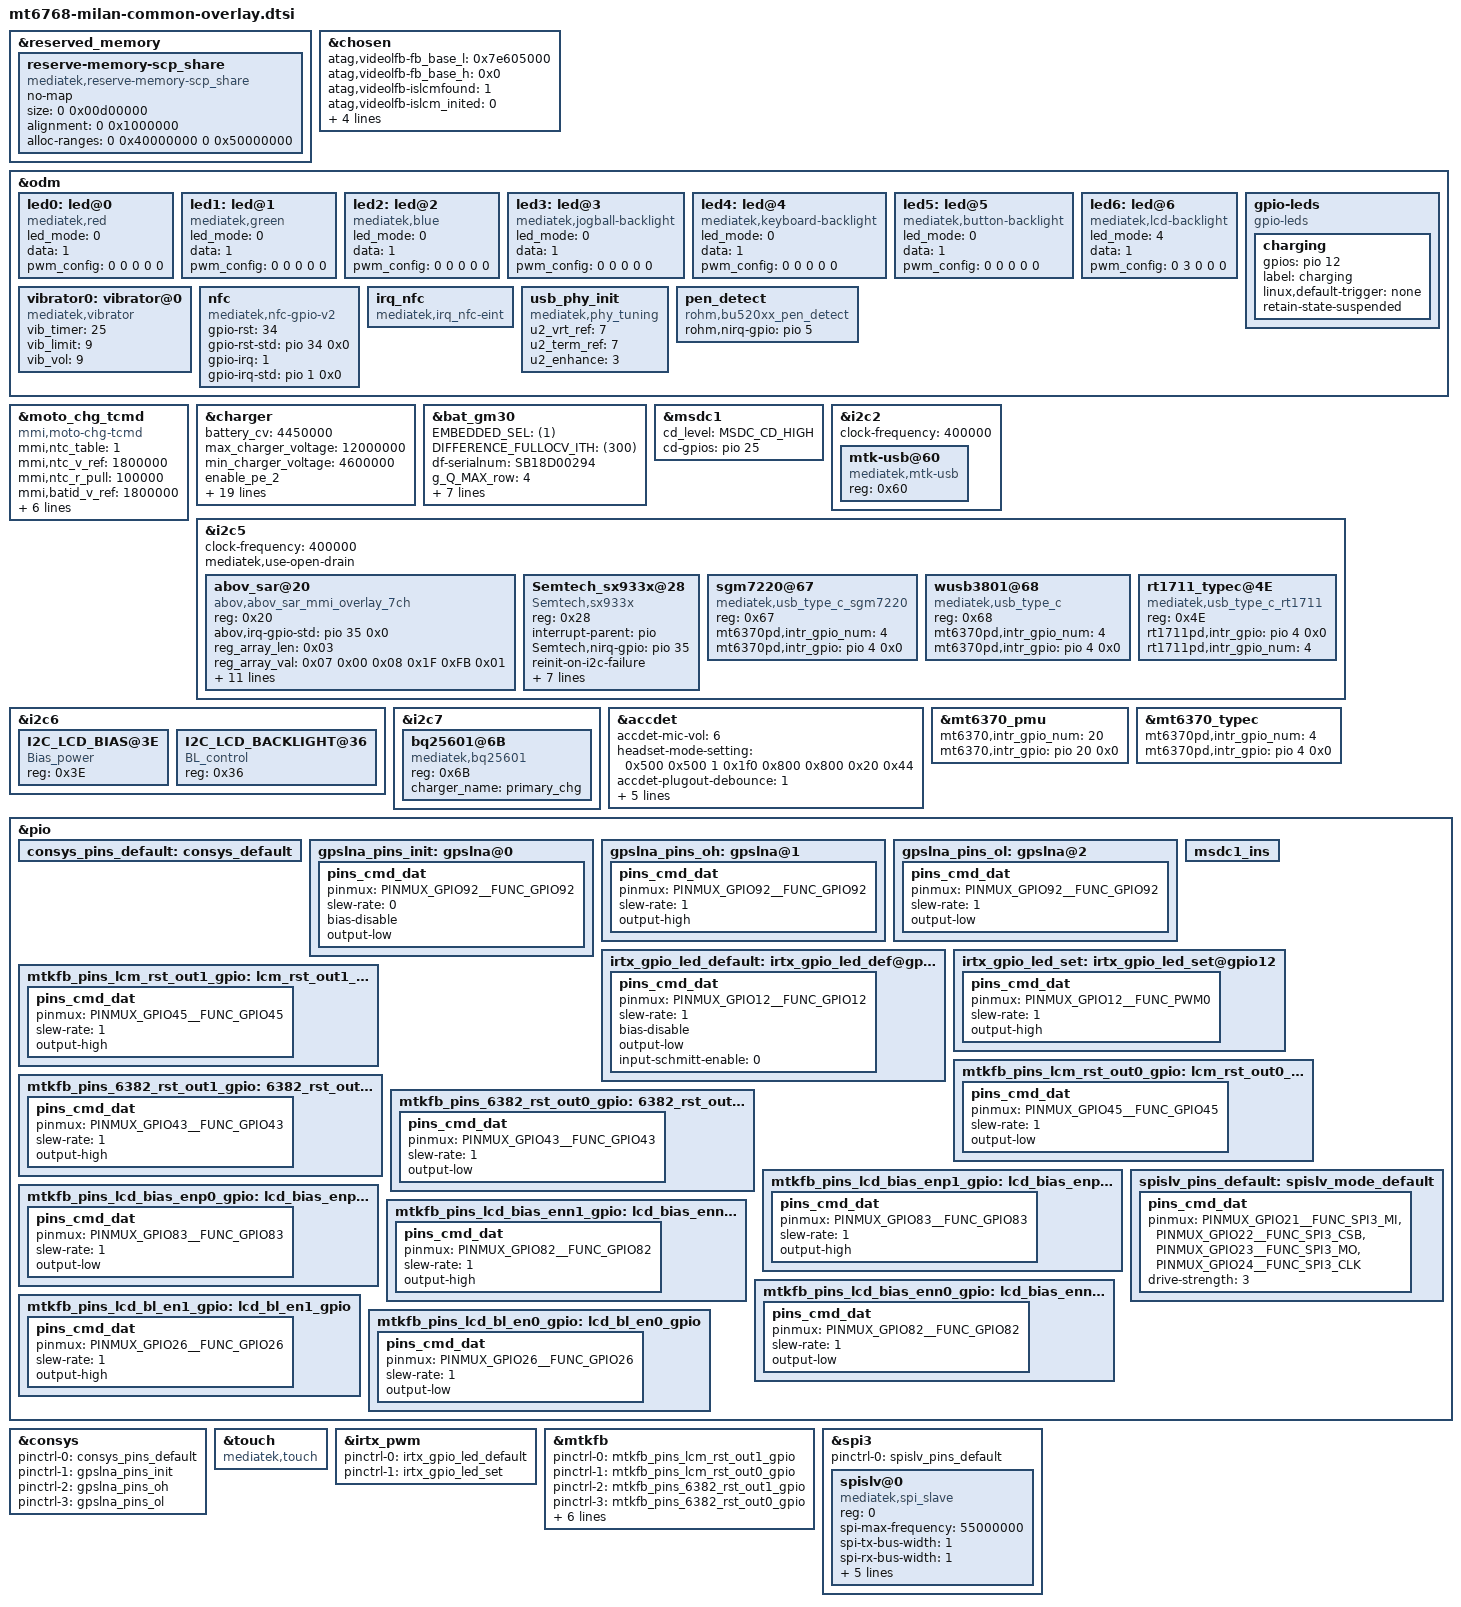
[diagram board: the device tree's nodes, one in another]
/* Copyright (c) 2021, Motorola Mobility Inc. All rights reserved.
 *
 * This program is free software; you can redistribute it and/or modify
 * it under the terms of the GNU General Public License version 2 and
 * only version 2 as published by the Free Software Foundation.
 *
 * This program is distributed in the hope that it will be useful,
 * but WITHOUT ANY WARRANTY; without even the implied warranty of
 * MERCHANTABILITY or FITNESS FOR A PARTICULAR PURPOSE.  See the
 * GNU General Public License for more details.
 */

#include "mediatek/mt6768-moto-common-overlay.dtsi"
#include "mediatek/mt6768-milan-audio-overlay.dtsi"
#include "mediatek/cust_mt6768_milan_touch_1080x2460.dtsi"
#include "dt-bindings/mmc/mt6768-msdc.h"

&reserved_memory {
	reserve-memory-scp_share {
		compatible = "mediatek,reserve-memory-scp_share";
		no-map;
		size = <0 0x00d00000>;
		alignment = <0 0x1000000>;
		alloc-ranges = <0 0x40000000 0 0x50000000>;
	};
};

/* chosen */
&chosen {

	atag,videolfb-fb_base_l = <0x7e605000>;
	atag,videolfb-fb_base_h = <0x0>;
	atag,videolfb-islcmfound = <1>;
	atag,videolfb-islcm_inited = <0>;
	atag,videolfb-fps= <6000>;
	atag,videolfb-vramSize= <0x017e8000>;
	atag,videolfb-lcmname=
		"hx83112b_fhdp_dsi_cmd_auo_rt5081_drv";
};

&odm {
	led0:led@0 {
		compatible = "mediatek,red";
		led_mode = <0>;
		data = <1>;
		pwm_config = <0 0 0 0 0>;
	};
	led1:led@1 {
		compatible = "mediatek,green";
		led_mode = <0>;
		data = <1>;
		pwm_config = <0 0 0 0 0>;
	};
	led2:led@2 {
		compatible = "mediatek,blue";
		led_mode = <0>;
		data = <1>;
		pwm_config = <0 0 0 0 0>;
	};
	led3:led@3 {
		compatible = "mediatek,jogball-backlight";
		led_mode = <0>;
		data = <1>;
		pwm_config = <0 0 0 0 0>;
	};
	led4:led@4 {
		compatible = "mediatek,keyboard-backlight";
		led_mode = <0>;
		data = <1>;
		pwm_config = <0 0 0 0 0>;
	};
	led5:led@5 {
		compatible = "mediatek,button-backlight";
		led_mode = <0>;
		data = <1>;
		pwm_config = <0 0 0 0 0>;
	};
	led6:led@6 {
		compatible = "mediatek,lcd-backlight";
		led_mode = <4>;
		data = <1>;
		pwm_config = <0 3 0 0 0>;
	};
	gpio-leds {
		compatible = "gpio-leds";
		status = "okay";
		charging {
		        gpios = <&pio 12 0x0>;
		        label = "charging";
		        linux,default-trigger = "none";
		        retain-state-suspended;
		};
	};
	vibrator0:vibrator@0 {
		compatible = "mediatek,vibrator";
		vib_timer = <25>;
		vib_limit = <9>;
		vib_vol= <9>;
	};
        nfc:nfc {
		compatible = "mediatek,nfc-gpio-v2";
		gpio-rst = <34>;
		gpio-rst-std = <&pio 34 0x0>;
		gpio-irq = <1>;
		gpio-irq-std = <&pio 1 0x0>;
	};

	irq_nfc: irq_nfc {
		compatible = "mediatek,irq_nfc-eint";
	};
    usb_phy_init:usb_phy_init {
        compatible = "mediatek,phy_tuning";
        u2_vrt_ref = <7>;
        u2_term_ref = <7>;
        u2_enhance = <3>;
    };
};

&moto_chg_tcmd {
                compatible = "mmi,moto-chg-tcmd";
                status = "okay";

                mmi,ntc_table = <1>;
                mmi,ntc_v_ref = <1800000>;
                mmi,ntc_r_pull = <100000>;

                mmi,batid_v_ref = <1800000>;
                mmi,batid_r_pull = <100000>;

                mmi,adc-channel-cpu = <0>;
                mmi,adc-channel-charger = <2>;
                mmi,adc-channel-pa = <1>;
                mmi,adc-channel-batid = <3>;
                mmi,adc-channel-vbat = <100>;
};

&charger {
        /* common */
        battery_cv = <4450000>;
        max_charger_voltage = <12000000>;
        min_charger_voltage = <4600000>;

        enable_pe_2;
        enable_sw_jeita;

        /* charging current */
        usb_charger_current_suspend = <0>;
        usb_charger_current_unconfigured = <70000>;
        usb_charger_current_configured = <500000>;
        usb_charger_current = <500000>;
        ac_charger_current = <2000000>;
        ac_charger_input_current = <2000000>;
        non_std_ac_charger_current = <1000000>;
        charging_host_charger_current = <1500000>;
        apple_1_0a_charger_current = <650000>;
        apple_2_1a_charger_current = <800000>;
        ta_ac_charger_current = <2000000>;

        /*mmi config*/
        mmi,iterm-ma = <242>;
        mmi,mmi-temp-zones = <0 4200 970 0>,
                        <10 4200 2500 970>,
                        <15 0 2500 2500>,
                        <45 0 3000 3000>,
                        <60 4200 2500 0>;
        mmi,enable-charging-limit;
        mmi,upper-limit-capacity = <65>;
        mmi,lower-limit-capacity = <60>;
};

&bat_gm30 {
        EMBEDDED_SEL = <(1)>;   /* embedded battery.*/
        DIFFERENCE_FULLOCV_ITH = <(300)>;       /*Charging termination current.*/
	  df-serialnum = "SB18D00294";
	  g_Q_MAX_row = <4>;
	  g_Q_MAX_col = <10>;
	  g_Q_MAX = <
		/*bat1,   bat2,   bat3,    bat4*/
		5010 5010 5010 5010/*T0*/
		5001 5001 5001 5001/*T1*/
		5098 5098 5098 5098/*T2*/
		5098 5098 5098 5098/*T3*/
		4851 4851 4851 4851/*T4*/
		3488 3488 3488 3488/*T5*/
		3488 3488 3488 3488/*T6*/
		3488 3488 3488 3488/*T7*/
		3488 3488 3488 3488/*T8*/
		3488 3488 3488 3488/*T9*/
	  >;
	  g_Q_MAX_H_CURRENT_row = <4>;
	  g_Q_MAX_H_CURRENT_col = <10>;
	  g_Q_MAX_H_CURRENT = <
		/*bat1,   bat2,   bat3,    bat4*/
		5010 5010 5010 5010/*T0*/
		5001 5001 5001 5001/*T1*/
		5098 5098 5098 5098/*T2*/
		5098 5098 5098 5098/*T3*/
		4851 4851 4851 4851/*T4*/
		3488 3488 3488 3488/*T5*/
		3488 3488 3488 3488/*T6*/
		3488 3488 3488 3488/*T7*/
		3488 3488 3488 3488/*T8*/
		3488 3488 3488 3488/*T9*/
	  >;
        #include "bat_setting/mt6768_battery_table_MD50_atl_5000mah_ext.dtsi"
};

&msdc1 {
        cd_level = /bits/ 8 <MSDC_CD_HIGH>;
	cd-gpios = <&pio 25 0>;
};

&i2c2 {
	clock-frequency = <400000>;

	mtk-usb@60 {
		compatible = "mediatek,mtk-usb";
		reg = <0x60>;
		status = "okay";
	};
};

&i2c5 {
    clock-frequency = <400000>;
    abov_sar@20 {
        compatible = "abov,abov_sar_mmi_overlay_7ch";
        reg = <0x20>;
        abov,irq-gpio-std = <&pio 35 0x0>;        //interrup gpio number,based on actual circuit configuration
        reg_array_len = <0x03>;
        reg_array_val = <0x07 0x00 0x08 0x1F 0xFB 0x01>;
        cap,use_channel_ch0 = <0x00>;
        cap,use_channel_ch1 = <0x01>;
        cap,use_channel_ch2 = <0x02>;
        ch0_name = "capsense_bottom_right";
        ch1_name = "capsense_bottom_left";
        ch2_name = "capsense_top";
        label = "AbovCapSense";  //firmware name,need pused AbovCapSense.BIN into /vendor/firmware/
        cap,channel_number = <0x03>;
        cap,fw_mode_ret = <0x39>;
        button_mask = <0x15>;
        cap,flash_erase_time = <1400>;
        status = "okay";
    };

    Semtech_sx933x@28 {
        status = "ok";
        compatible = "Semtech,sx933x";
        reg = <0x28>;
        interrupt-parent = <&pio>;
        Semtech,nirq-gpio = <&pio 35 0x0>;
        /*use PH3/4 as the reference sensor
        set it to 0xff if the ref-phases-x is not used*/
        reinit-on-i2c-failure;
        reinit-on-irq-failure;
        Semtech,button-flag = <0x0f>;
        Semtech,ref-phases-a = <3>;
        Semtech,ref-phases-b = <4>;
        Semtech,reg-num = <83>;
        Semtech,reg-init = <
	0x8020 0x001F0000
	0x4004 0x00000074
	0x4008 0x00000000
	0x4054 0x00000400
	0x42C0 0x08000000
	0x42C4 0x0000003F
	0x800C 0x00000000
	0x8010 0x00000000
	0x8014 0x00000000
	0x8018 0x00000000
	0x801C 0x00000031
	0x8024 0x10000A6E
	0x8028 0x2FFF82C8
	0x802C 0x00000A66
	0x8030 0x3FF78024
	0x8034 0x10000A6E
	0x8038 0x3FFE82E6
	0x803C 0x10000A5E
	0x8040 0x3DFF8263
	0x8044 0x00000A66
	0x8048 0x3FBF82C0
	0x804C 0x0000088E
	0x8050 0x80001EE6
	0x8054 0x10223705
	0x8058 0x20630031
	0x805C 0x78A45000
	0x8060 0x00000000
	0x8064 0x00000000
	0x8068 0x00000000
	0x806C 0x00000000
	0x8070 0x00000000
	0x8074 0x10222605
	0x8078 0x20630031
	0x807C 0x789C5000
	0x8080 0x00000000
	0x8084 0x00440000
	0x8088 0x00000000
	0x808C 0x20002000
	0x8090 0x00010000
	0x8094 0x10223705
	0x8098 0x20630031
	0x809C 0x789C5000
	0x80A0 0x00000000
	0x80A4 0x00700000
	0x80A8 0x00000000
	0x80AC 0x1F001F00
	0x80B0 0x00010000
	0x80B4 0x10224400
	0x80B8 0x20630031
	0x80BC 0x789C5000
	0x80C0 0x00000000
	0x80C4 0x00000000
	0x80C8 0x00000000
	0x80CC 0x00000000
	0x80D0 0x00000000
	0x80D4 0x1652FF00
	0x80D8 0x20630031
	0x80DC 0x54AC5000
	0x80E0 0x00000000
	0x80E4 0x00000000
	0x80E8 0x00000000
	0x80EC 0x00000000
	0x80F0 0x00000000
	0x80F4 0x10162800
	0x80F8 0x20400031
	0x80FC 0x54AC5300
	0x8100 0x00000000
	0x8104 0x00000000
	0x8108 0x00000000
	0x810C 0x00000000
	0x8110 0x00000000
	0x8124 0x0400000C
	0x8128 0x0000000C
	0x812C 0x00000000
	0x8130 0x00000000
	0x8134 0x00000000
	0x8138 0x00000000
	0x813C 0x00000000
	0x8140 0x00000000
	0x8144 0x00000000
	0x8148 0x00000000
	0x814C 0x00000000
	0x81A4 0x01D00008
	0x8020 0x001F001F
	0x4280 0x0000000E
        >;
    };
};

/* Config typec */
&i2c5 {
	clock-frequency = <400000>;
	mediatek,use-open-drain;
	sgm7220@67 {
		compatible = "mediatek,usb_type_c_sgm7220";
		reg = <0x67>;
		mt6370pd,intr_gpio_num = <4>; /* direct defined GPIO num */
		mt6370pd,intr_gpio = <&pio 4 0x0>;
		status = "okay";
	};

	wusb3801@68 {
		compatible = "mediatek,usb_type_c";
		reg = <0x68>;
		mt6370pd,intr_gpio_num = <4>; /* direct defined GPIO num */
		mt6370pd,intr_gpio = <&pio 4 0x0>;
		status = "okay";
	};

	rt1711_typec@4E {
		compatible = "mediatek,usb_type_c_rt1711";
		reg = <0x4E>;
		rt1711pd,intr_gpio = <&pio 4 0x0>;
		rt1711pd,intr_gpio_num = <4>;
		status = "okay";
	};
};

/* Config backlight */
&i2c6{
	I2C_LCD_BIAS@3E {
		compatible = "Bias_power";
		reg = <0x3E>;
		status = "okay";
	};
	I2C_LCD_BACKLIGHT@36 {
		compatible = "BL_control";
		reg = <0x36>;
		status = "okay";
	};
};

/* Config charger */
&i2c7{
	bq25601@6B {
		status = "okay";
		compatible = "mediatek,bq25601";
		reg = <0x6B>;
		charger_name = "primary_chg";
	};
};
/*config stylus pen*/
&odm {
    pen_detect: pen_detect {
       compatible = "rohm,bu520xx_pen_detect";
       rohm,nirq-gpio = <&pio 5 0x00>;
    };
};

/* accdet start */
&accdet {
	/* accdet micbias voltage: 0x07,2.7v;0x05,2.5v;0x02,1.9v */
	accdet-mic-vol = <6>;
	headset-mode-setting = <0x500 0x500 1 0x1f0 0x800 0x800 0x20 0x44>;
	accdet-plugout-debounce = <1>;
	/*1:ACC mode, 2:low cost without in bias, 6:low cost with in bias*/
	accdet-mic-mode = <1>;
	/* eint_level_trigger: 8,LEVEL_LOW(DEF) ;4,LV_HIGH;others,LV_LOW */
	headset-eint-level-pol = <8>;
	/*0--MD_MAX--UP_MAX--DW_MAX*/
	headset-three-key-threshold = <0 80 220 400>;
	headset-three-key-threshold-CDD = <0 121 192 600>;
	/*0--MD_MAX--VOICE_MAX--UP_MAX--DW_MAX*/
	headset-four-key-threshold = <0 58 121 192 400>;
	status = "okay";
};
/* accdet end */

&mt6370_pmu {
	mt6370,intr_gpio_num = <20>; /* direct defined GPIO num */
	mt6370,intr_gpio = <&pio 20 0x0>;
};
&mt6370_typec {
	mt6370pd,intr_gpio_num = <4>; /* direct defined GPIO num */
	mt6370pd,intr_gpio = <&pio 4 0x0>;
};

/* CONSYS GPIO standardization */
&pio {
	consys_pins_default: consys_default {
	};
	gpslna_pins_init: gpslna@0 {
		pins_cmd_dat {
			pinmux = <PINMUX_GPIO92__FUNC_GPIO92>;
			slew-rate = <0>;
			bias-disable;
			output-low;
		};
	};
	gpslna_pins_oh: gpslna@1 {
		pins_cmd_dat {
			pinmux = <PINMUX_GPIO92__FUNC_GPIO92>;
			slew-rate = <1>;
			output-high;
		};
	};
	gpslna_pins_ol: gpslna@2 {
		pins_cmd_dat {
			pinmux = <PINMUX_GPIO92__FUNC_GPIO92>;
			slew-rate = <1>;
			output-low;
		};
	};
        msdc1_ins: msdc1_ins {
	};
};
&consys {
	pinctrl-names = "default", "gps_lna_state_init",
		"gps_lna_state_oh", "gps_lna_state_ol";
	pinctrl-0 = <&consys_pins_default>;
	pinctrl-1 = <&gpslna_pins_init>;
	pinctrl-2 = <&gpslna_pins_oh>;
	pinctrl-3 = <&gpslna_pins_ol>;
	status = "okay";
};
/* CONSYS end */

&touch {
	compatible = "mediatek,touch";
};

/* IRTX GPIO Start */
&irtx_pwm {
	pinctrl-names = "irtx_gpio_led_default", "irtx_gpio_led_set";
	pinctrl-0 = <&irtx_gpio_led_default>;
	pinctrl-1 = <&irtx_gpio_led_set>;
	status = "okay";
};
&pio {
	/* IRTX GPIO Settings -Start */
	/* default: GPIO0, output, high */
	irtx_gpio_led_default:irtx_gpio_led_def@gpio12 {
		pins_cmd_dat {
			pinmux = <PINMUX_GPIO12__FUNC_GPIO12>;
			slew-rate = <1>;
			bias-disable;
			output-low;
			input-schmitt-enable = <0>;
		};
	};

	irtx_gpio_led_set:irtx_gpio_led_set@gpio12 {
		pins_cmd_dat {
			pinmux = <PINMUX_GPIO12__FUNC_PWM0>;
			slew-rate = <1>;
			output-high;
		};
	};
}; /* IRTX GPIO Settings -End */

/* DISPSYS GPIO standardization */
&pio {
	mtkfb_pins_lcm_rst_out1_gpio: lcm_rst_out1_gpio {
		pins_cmd_dat {
			pinmux = <PINMUX_GPIO45__FUNC_GPIO45>;
			slew-rate = <1>;
			output-high;
		};
	};

	mtkfb_pins_lcm_rst_out0_gpio: lcm_rst_out0_gpio {
		pins_cmd_dat {
			pinmux = <PINMUX_GPIO45__FUNC_GPIO45>;
			slew-rate = <1>;
			output-low;
		};
	};

	mtkfb_pins_6382_rst_out1_gpio: 6382_rst_out1_gpio {
		pins_cmd_dat {
			pinmux = <PINMUX_GPIO43__FUNC_GPIO43>;
			slew-rate = <1>;
			output-high;
		};
	};

	mtkfb_pins_6382_rst_out0_gpio: 6382_rst_out0_gpio {
		pins_cmd_dat {
			pinmux = <PINMUX_GPIO43__FUNC_GPIO43>;
			slew-rate = <1>;
			output-low;
		};
	};

	mtkfb_pins_lcd_bias_enp1_gpio: lcd_bias_enp1_gpio {
		pins_cmd_dat {
			pinmux = <PINMUX_GPIO83__FUNC_GPIO83>;
			slew-rate = <1>;
			output-high;
		};
	};

	mtkfb_pins_lcd_bias_enp0_gpio: lcd_bias_enp0_gpio {
		pins_cmd_dat {
			pinmux = <PINMUX_GPIO83__FUNC_GPIO83>;
			slew-rate = <1>;
			output-low;
		};
	};

	mtkfb_pins_lcd_bias_enn1_gpio: lcd_bias_enn1_gpio {
		pins_cmd_dat {
			pinmux = <PINMUX_GPIO82__FUNC_GPIO82>;
			slew-rate = <1>;
			output-high;
		};
	};

	mtkfb_pins_lcd_bias_enn0_gpio: lcd_bias_enn0_gpio {
		pins_cmd_dat {
			pinmux = <PINMUX_GPIO82__FUNC_GPIO82>;
			slew-rate = <1>;
			output-low;
		};
	};

	mtkfb_pins_lcd_bl_en1_gpio: lcd_bl_en1_gpio {
		pins_cmd_dat {
			pinmux = <PINMUX_GPIO26__FUNC_GPIO26>;
			slew-rate = <1>;
			output-high;
		};
	};

	mtkfb_pins_lcd_bl_en0_gpio: lcd_bl_en0_gpio {
		pins_cmd_dat {
			pinmux = <PINMUX_GPIO26__FUNC_GPIO26>;
			slew-rate = <1>;
			output-low;
		};
	};
};

&mtkfb {
	pinctrl-names =
		"lcm_rst_out1_gpio", "lcm_rst_out0_gpio",
		"6382_rst_out1_gpio", "6382_rst_out0_gpio",
		"lcd_bias_enp1_gpio","lcd_bias_enp0_gpio",
		"lcd_bias_enn1_gpio","lcd_bias_enn0_gpio",
		"lcd_bl_en1_gpio","lcd_bl_en0_gpio";

	pinctrl-0 = <&mtkfb_pins_lcm_rst_out1_gpio>;
	pinctrl-1 = <&mtkfb_pins_lcm_rst_out0_gpio>;
	pinctrl-2 = <&mtkfb_pins_6382_rst_out1_gpio>;
	pinctrl-3 = <&mtkfb_pins_6382_rst_out0_gpio>;
	pinctrl-4 = <&mtkfb_pins_lcd_bias_enp1_gpio>;
	pinctrl-5 = <&mtkfb_pins_lcd_bias_enp0_gpio>;
	pinctrl-6 = <&mtkfb_pins_lcd_bias_enn1_gpio>;
	pinctrl-7 = <&mtkfb_pins_lcd_bias_enn0_gpio>;
	pinctrl-8 = <&mtkfb_pins_lcd_bl_en1_gpio>;
	pinctrl-9 = <&mtkfb_pins_lcd_bl_en0_gpio>;
	status = "okay";
};

&spi3 {
	status = "okay";
	#address-cells = <1>;
	#size-cells = <0>;
	pinctrl-names = "default";
	pinctrl-0 = <&spislv_pins_default>;

	spislv@0 {
		compatible = "mediatek,spi_slave";
		reg = <0>;
		spi-max-frequency = <55000000>;
		spi-tx-bus-width = <1>;
		spi-rx-bus-width = <1>;
		low-speed-tick-delay = /bits/ 8 <1>;
		low-speed-early-trans = /bits/ 8 <0>;
		high-speed-tick-delay = /bits/ 8 <1>;
		high-speed-early-trans = /bits/ 8 <1>;
		slave-drive-strength = /bits/ 8 <3>;
	};
};

&pio {
	spislv_pins_default: spislv_mode_default {
		pins_cmd_dat {
			pinmux = <PINMUX_GPIO21__FUNC_SPI3_MI>,
				<PINMUX_GPIO22__FUNC_SPI3_CSB>,
				<PINMUX_GPIO23__FUNC_SPI3_MO>,
				<PINMUX_GPIO24__FUNC_SPI3_CLK>;
			drive-strength = <3>;
		};
	};
};

/* DISPSYS GPIO standardization end*/

/*End of this file, DO NOT ADD ANYTHING HERE*/
